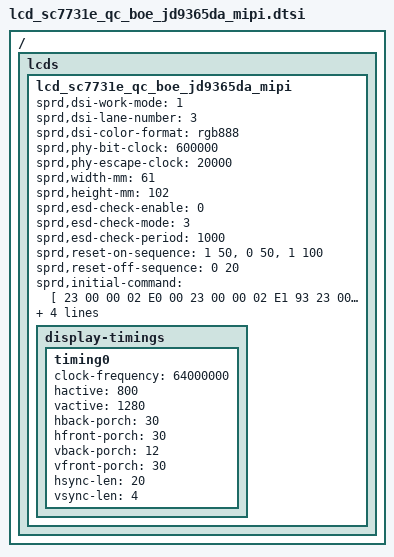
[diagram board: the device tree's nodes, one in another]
/ { lcds {
	lcd_sc7731e_qc_boe_jd9365da_mipi: lcd_sc7731e_qc_boe_jd9365da_mipi {

		sprd,dsi-work-mode = <1>;
		sprd,dsi-lane-number = <3>;
		sprd,dsi-color-format = "rgb888";

		sprd,phy-bit-clock = <600000>;
		sprd,phy-escape-clock = <20000>;

		sprd,width-mm = <61>;
		sprd,height-mm = <102>;

		sprd,esd-check-enable = <0>;
		sprd,esd-check-mode = <3>;
		sprd,esd-check-period = <1000>;
		/*sprd,esd-check-register = <0x0A>;*/
		/*sprd,esd-check-value = <0x9C>;*/

		sprd,reset-on-sequence = <1 50>, <0 50>, <1 100>;
		sprd,reset-off-sequence = <0 20>;

		sprd,initial-command = [
//JD9365D initial code

//Page0
			  23 00 00 02 E0 00 

//--- PASSWORD  ----//
			  23 00 00 02 E1 93 
			  23 00 00 02 E2 65 
			  23 00 00 02 E3 F8 
			  23 00 00 02 80 02 



//--- Page1  ----//
			  23 00 00 02 E0 01 

//Set VCOM
			  23 00 00 02 00 00 
			  23 00 00 02 01 3A  //0x35
			  23 00 00 02 03 00 
			  23 00 00 02 04 3D 

//VCSW1
			  23 00 00 02 0C 74 

//Set Gamma Power  VGMP VGMN VGSP VGSN
			  23 00 00 02 17 00 
			  23 00 00 02 18 F7 //5.2V  BF=4.5V
			  23 00 00 02 19 00 //0.3V
			  23 00 00 02 1A 00 
			  23 00 00 02 1B F7 
			  23 00 00 02 1C 00 
                
			  23 00 00 02 24 FE //VCL_REG enable


			  23 00 00 02 35 23 	//SAP

			  23 00 00 02 37 09 	//SS=1 BGR=1

//SET RGBCYC
			  23 00 00 02 38 04 	//JDT=101 zigzag inversion
			  23 00 00 02 39 00 
			  23 00 00 02 3A 01 
			  23 00 00 02 3C 70 	//SET EQ3 for TE_H
			  23 00 00 02 3D FF 	//SET CHGEN_ON
			  23 00 00 02 3E FF 	//SET CHGEN_OFF 
			  23 00 00 02 3F 7F 	//SET CHGEN_OFF2


//Set TCON
			  23 00 00 02 40 06 	//RSO=
			  23 00 00 02 41 A0 	//LN=640->1280 line
			  23 00 00 02 43 1E 	//VFP=30
			  23 00 00 02 44 0B 	//VBP=12
			  23 00 00 02 45 28   //HBP=40

//--- power voltage  ----//
			  23 00 00 02 55 01 	//DCDCM=1111
//			  23 00 00 02 56 01 
			  23 00 00 02 57 A9 
//			  23 00 00 02 58 0A 
			  23 00 00 02 59 0A 	//VCL = -2.5V
			  23 00 00 02 5A 2D 	//VGH = 16V
			  23 00 00 02 5B 1A 	//VGL = -12V
			  23 00 00 02 5C 15 	//pump clk


//--- Gamma  ----//      //G2.2 
			  23 00 00 02 5D 7F    //0x7F 
			  23 00 00 02 5E 70    //0x70 
			  23 00 00 02 5F 64    //0x64 
			  23 00 00 02 60 5A    //0x5A 
			  23 00 00 02 61 58    //0x58 
			  23 00 00 02 62 4B    //0x4B 
			  23 00 00 02 63 51    //0x51 
			  23 00 00 02 64 3C    //0x3C 
			  23 00 00 02 65 56    //0x56 
			  23 00 00 02 66 56    //0x56 
			  23 00 00 02 67 55    //0x55 
			  23 00 00 02 68 70    //0x70 
			  23 00 00 02 69 5B    //0x5B 
			  23 00 00 02 6A 5F    //0x5F 
			  23 00 00 02 6B 4F    //0x4F 
			  23 00 00 02 6C 49    //0x49 
			  23 00 00 02 6D 3B    //0x3B 
			  23 00 00 02 6E 29    //0x29 
			  23 00 00 02 6F 02    //0x02 
			  23 00 00 02 70 7F    //0x7F 
			  23 00 00 02 71 70    //0x70 
			  23 00 00 02 72 64    //0x64 
			  23 00 00 02 73 5A    //0x5A 
			  23 00 00 02 74 58    //0x58 
			  23 00 00 02 75 4B    //0x4B 
			  23 00 00 02 76 51    //0x51 
			  23 00 00 02 77 3C    //0x3C 
			  23 00 00 02 78 56    //0x56 
			  23 00 00 02 79 56    //0x56 
			  23 00 00 02 7A 55    //0x55 
			  23 00 00 02 7B 70    //0x70 
			  23 00 00 02 7C 5B    //0x5B 
			  23 00 00 02 7D 5F    //0x5F 
			  23 00 00 02 7E 4F    //0x4F 
			  23 00 00 02 7F 49    //0x49 
			  23 00 00 02 80 3B    //0x3B 
			  23 00 00 02 81 29    //0x29 
			  23 00 00 02 82 02    //0x02 


//Page2  for GIP
			  23 00 00 02 E0 02 

//GIP_L Pin mapping
			  23 00 00 02 00 50 //STV2_ODD 
			  23 00 00 02 01 5F //VSSG_ODD 
			  23 00 00 02 02 5F //VSSG_ODD 
			  23 00 00 02 03 52 //RESET_ODD
			  23 00 00 02 04 77 //VDD2_ODD 
			  23 00 00 02 05 57 //VDD1_ODD 
			  23 00 00 02 06 5F //X     
			  23 00 00 02 07 4E //CK11     
			  23 00 00 02 08 4C //CK9      
			  23 00 00 02 09 5F //X     
			  23 00 00 02 0A 4A //CK7      
			  23 00 00 02 0B 48 //CK5      
			  23 00 00 02 0C 5F //X     
			  23 00 00 02 0D 46 //CK3      
			  23 00 00 02 0E 44 //CK1      
			  23 00 00 02 0F 40 //STV1_ODD 
			  23 00 00 02 10 5F //X     
			  23 00 00 02 11 5F //X     
			  23 00 00 02 12 5F //X     
			  23 00 00 02 13 5F //X     
			  23 00 00 02 14 5F //X     
			  23 00 00 02 15 5F //X     

//GIP_R Pin mapping
			  23 00 00 02 16 51 //STV2_EVEN  
			  23 00 00 02 17 5F //VSSG_EVEN  
			  23 00 00 02 18 5F //VSSG_EVEN  
			  23 00 00 02 19 53 //RESET__EVEN
			  23 00 00 02 1A 77 //VDD2_EVEN  
			  23 00 00 02 1B 57 //VDD1_EVEN  
			  23 00 00 02 1C 5F //X       
			  23 00 00 02 1D 4F //CK12       
			  23 00 00 02 1E 4D //CK10       
			  23 00 00 02 1F 5F //X       
			  23 00 00 02 20 4B //CK8        
			  23 00 00 02 21 49 //CK6        
			  23 00 00 02 22 5F //X       
			  23 00 00 02 23 47 //CK4        
			  23 00 00 02 24 45 //CK2        
			  23 00 00 02 25 41 //STV1_EVEN  
			  23 00 00 02 26 5F //X       
			  23 00 00 02 27 5F //X       
			  23 00 00 02 28 5F //X       
			  23 00 00 02 29 5F //X       
			  23 00 00 02 2A 5F //X       
			  23 00 00 02 2B 5F //X       
                      
//GIP_L_GS Pin mapping
			  23 00 00 02 2C 01 //STV2_ODD       
			  23 00 00 02 2D 1F //VSSG_ODD          
			  23 00 00 02 2E 1F //VSSG_ODD        
			  23 00 00 02 2F 13 //RESET_ODD       
			  23 00 00 02 30 17 //VDD2_ODD        
			  23 00 00 02 31 17 //VDD1_ODD        
			  23 00 00 02 32 1F //X            
			  23 00 00 02 33 0D //CK11            
			  23 00 00 02 34 0F //CK9             
			  23 00 00 02 35 1F //X            
			  23 00 00 02 36 05 //CK7             
			  23 00 00 02 37 07 //CK5             
			  23 00 00 02 38 1F //X            
			  23 00 00 02 39 09 //CK3             
			  23 00 00 02 3A 0B //CK1             
			  23 00 00 02 3B 11 //STV1_ODD        
			  23 00 00 02 3C 1F //X            
			  23 00 00 02 3D 1F //X            
			  23 00 00 02 3E 1F //X            
			  23 00 00 02 3F 1F //X            
			  23 00 00 02 40 1F //X            
			  23 00 00 02 41 1F //X           
                                       
//GIP_R_GS Pin mapping                 
			  23 00 00 02 42 00 //STV2_EVEN      
			  23 00 00 02 43 1F //VSSG_EVEN         
			  23 00 00 02 44 1F //VSSG_EVEN       
			  23 00 00 02 45 12 //RESET__EVEN     
			  23 00 00 02 46 17 //VDD2_EVEN       
			  23 00 00 02 47 17 //VDD1_EVEN       
			  23 00 00 02 48 1F //X            
			  23 00 00 02 49 0C //CK12            
			  23 00 00 02 4A 0E //CK10            
			  23 00 00 02 4B 1F //X            
			  23 00 00 02 4C 04 //CK8             
			  23 00 00 02 4D 06 //CK6             
			  23 00 00 02 4E 1F //X            
			  23 00 00 02 4F 08 //CK4             
			  23 00 00 02 50 0A //CK2              
			  23 00 00 02 51 10 //STV1_EVEN       
			  23 00 00 02 52 1F //X            
			  23 00 00 02 53 1F //X            
			  23 00 00 02 54 1F //X            
			  23 00 00 02 55 1F //X            
			  23 00 00 02 56 1F //X            
			  23 00 00 02 57 1F //X            

//GIP Timing  
			  23 00 00 02 58 40  
//			  23 00 00 02 59 00  
//			  23 00 00 02 5A 00  
			  23 00 00 02 5B 10  
			  23 00 00 02 5C 06 //STV_S0 
			  23 00 00 02 5D 40  
			  23 00 00 02 5E 00  
			  23 00 00 02 5F 00  
			  23 00 00 02 60 40 //ETV_W 
			  23 00 00 02 61 03  
			  23 00 00 02 62 04  
			  23 00 00 02 63 6C //CKV_ON 
			  23 00 00 02 64 6C //CKV_OFF 
			  23 00 00 02 65 75  
			  23 00 00 02 66 08 //ETV_S0 
			  23 00 00 02 67 B4  //ckv_num/ckv_w
			  23 00 00 02 68 08  //CKV_S0
			  23 00 00 02 69 6C //CKV_ON
			  23 00 00 02 6A 6C //CKV_OFF 
			  23 00 00 02 6B 0C  //dummy
//			  23 00 00 02 6C 00 //GEQ_LINE 
			  23 00 00 02 6D 00 //GGND1 
			  23 00 00 02 6E 00 //GGND2 
			  23 00 00 02 6F 88  
//			  23 00 00 02 70 00  
//			  23 00 00 02 71 00  
//			  23 00 00 02 72 06  
//			  23 00 00 02 73 7B  
//			  23 00 00 02 74 00  
			  23 00 00 02 75 BB //FLM_EN 
			  23 00 00 02 76 00  
			  23 00 00 02 77 05  
			  23 00 00 02 78 2A //FLM_OFF 
//			  23 00 00 02 79 00  
//			  23 00 00 02 7A 00  
//			  23 00 00 02 7B 00  
//			  23 00 00 02 7C 00  
//			  23 00 00 02 7D 03  
//			  23 00 00 02 7E 7B  

//Page3
			  23 00 00 02 E0 03 
			  23 00 00 02 9A 01 
			  23 00 00 02 9B 02 //Source EQ option
			  23 00 00 02 AF 01 //CABC TP


//Page4
			  23 00 00 02 E0 04 
			  23 00 00 02 02 23 
			  23 00 00 02 09 11 
			  23 00 00 02 0E 48 //Source EQ option
			  23 00 00 02 36 49 
			  23 00 00 02 96 0A //CABC 8 bits 12=10bit


//Page0
			  23 00 00 02 E0 00 
			  23 00 00 02 51 80 
			  23 00 00 02 53 2C 
			  23 00 00 02 55 00 

			13 78 00 01 11
			13 64 00 01 29
			];
		sprd,sleep-in-command = [
			13 0A 00 01 28
			13 78 00 01 10
			];
		sprd,sleep-out-command = [
			13 78 00 01 11
			13 64 00 01 29
			];

		display-timings {
			timing0 {
			clock-frequency = <64000000>;
			hactive = <800>;
			vactive = <1280>;
			hback-porch = <30>;
			hfront-porch = <30>;
			vback-porch = <12>;
			vfront-porch = <30>;
			hsync-len = <20>;
			vsync-len = <4>;
			};
		};
	};
};};

